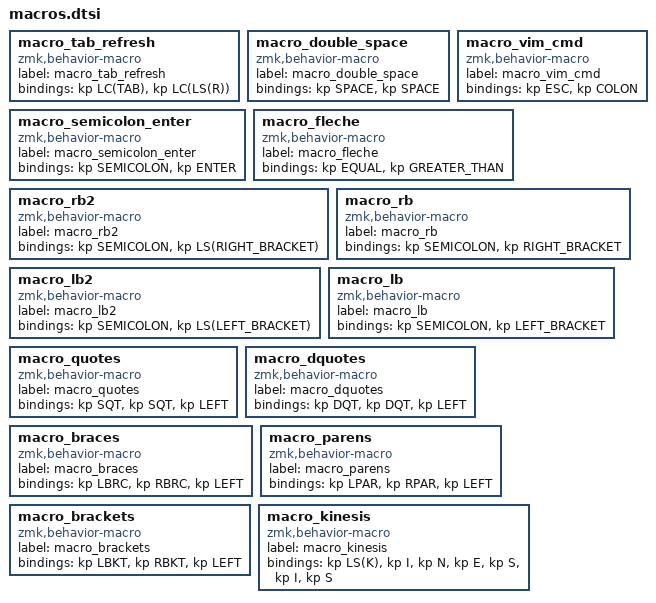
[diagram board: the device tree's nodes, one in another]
macro_tab_refresh: macro_tab_refresh{
compatible = "zmk,behavior-macro";
label = "macro_tab_refresh";
#binding-cells = <0>;
bindings = <&kp LC(TAB)>, <&kp LC(LS(R))>;
};
macro_double_space: macro_double_space{
compatible = "zmk,behavior-macro";
label = "macro_double_space";
#binding-cells = <0>;
bindings = <&kp SPACE>, <&kp SPACE>;
};
macro_vim_cmd: macro_vim_cmd{
compatible = "zmk,behavior-macro";
label = "macro_vim_cmd";
#binding-cells = <0>;
bindings = <&kp ESC>, <&kp COLON>;
};
macro_semicolon_enter: macro_semicolon_enter{
compatible = "zmk,behavior-macro";
label = "macro_semicolon_enter";
#binding-cells = <0>;
bindings = <&kp SEMICOLON>, <&kp ENTER>;
};
macro_fleche: macro_fleche{
compatible = "zmk,behavior-macro";
label = "macro_fleche";
#binding-cells = <0>;
bindings = <&kp EQUAL>, <&kp GREATER_THAN>;
};
macro_rb2: macro_rb2{
compatible = "zmk,behavior-macro";
label = "macro_rb2";
#binding-cells = <0>;
bindings = <&kp SEMICOLON>, <&kp LS(RIGHT_BRACKET)>;
};
macro_rb: macro_rb{
compatible = "zmk,behavior-macro";
label = "macro_rb";
#binding-cells = <0>;
bindings = <&kp SEMICOLON>, <&kp RIGHT_BRACKET>;
};
macro_lb2: macro_lb2{
compatible = "zmk,behavior-macro";
label = "macro_lb2";
#binding-cells = <0>;
bindings = <&kp SEMICOLON>, <&kp LS(LEFT_BRACKET)>;
};
macro_lb: macro_lb{
compatible = "zmk,behavior-macro";
label = "macro_lb";
#binding-cells = <0>;
bindings = <&kp SEMICOLON>, <&kp LEFT_BRACKET>;
};
macro_quotes: macro_quotes{
compatible = "zmk,behavior-macro";
label = "macro_quotes";
#binding-cells = <0>;
bindings = <&kp SQT>, <&kp SQT>, <&kp LEFT>;
};
macro_dquotes: macro_dquotes{
compatible = "zmk,behavior-macro";
label = "macro_dquotes";
#binding-cells = <0>;
bindings = <&kp DQT>, <&kp DQT>, <&kp LEFT>;
};
macro_braces: macro_braces{
compatible = "zmk,behavior-macro";
label = "macro_braces";
#binding-cells = <0>;
bindings = <&kp LBRC>, <&kp RBRC>, <&kp LEFT>;
};
macro_parens: macro_parens{
compatible = "zmk,behavior-macro";
label = "macro_parens";
#binding-cells = <0>;
bindings = <&kp LPAR>, <&kp RPAR>, <&kp LEFT>;
};
macro_brackets: macro_brackets{
compatible = "zmk,behavior-macro";
label = "macro_brackets";
#binding-cells = <0>;
bindings = <&kp LBKT>, <&kp RBKT>, <&kp LEFT>;
};
macro_kinesis: macro_kinesis{
compatible = "zmk,behavior-macro";
label = "macro_kinesis";
#binding-cells = <0>;
bindings = <&kp LS(K)>, <&kp I>, <&kp N>, <&kp E>, <&kp S>, <&kp I>, <&kp S>;
};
